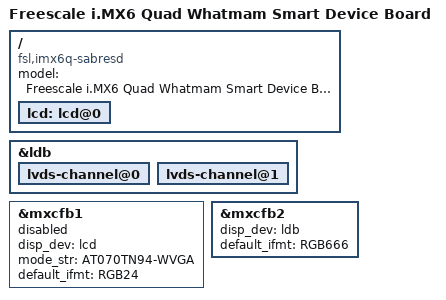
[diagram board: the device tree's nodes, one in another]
// SPDX-License-Identifier: GPL-2.0+
//
// Copyright 2012 Freescale Semiconductor, Inc.
// Copyright 2011 Linaro Ltd.

/dts-v1/;

#include "imx6q.dtsi"
#include "imx6qdl-JW-incu6.dtsi"

/ {
	model = "Freescale i.MX6 Quad Whatmam Smart Device Board";
	compatible = "fsl,imx6q-sabresd", "fsl,imx6q";

	lcd: lcd@0 {
        //status = "okay";
        status = "disabled";

    };
};

&ldb {
	lvds-channel@0 {
	};

	lvds-channel@1 {
	status = "okay";
	};
};

&lcd {
    status = "okay";
};

&mxcfb1 {
	status = "okay";
	disp_dev = "lcd";
    mode_str ="AT070TN94-WVGA";
    default_ifmt = "RGB24";
    //status = "okay";
    status = "disabled";

};

&mxcfb2 {
	disp_dev = "ldb";
    default_ifmt = "RGB666";
    status = "okay";
};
